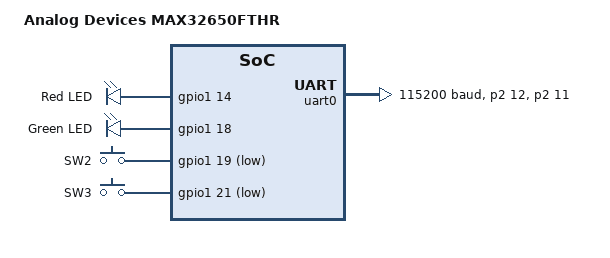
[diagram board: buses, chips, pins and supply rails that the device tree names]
/*
 * Copyright (c) 2025 Analog Devices, Inc.
 *
 * SPDX-License-Identifier: Apache-2.0
 */

/dts-v1/;

#include <adi/max32/max32650.dtsi>
#include <adi/max32/max32650-pinctrl.dtsi>
#include <zephyr/dt-bindings/gpio/adi-max32-gpio.h>
#include <zephyr/dt-bindings/input/input-event-codes.h>

/ {
	model = "Analog Devices MAX32650FTHR";
	compatible = "adi,max32650fthr";

	chosen {
		zephyr,console = &uart0;
		zephyr,shell-uart = &uart0;
		zephyr,sram = &sram0;
		zephyr,flash = &flash0;
	};

	leds {
		compatible = "gpio-leds";

		led1: led_1 {
			gpios = <&gpio1 14 GPIO_ACTIVE_HIGH>;
			label = "Red LED";
		};

		led2: led_2 {
			gpios = <&gpio1 18 GPIO_ACTIVE_HIGH>;
			label = "Green LED";
		};
	};

	buttons {
		compatible = "gpio-keys";

		pb1: pb1 {
			gpios = <&gpio1 19 (GPIO_PULL_UP | GPIO_ACTIVE_LOW)>;
			label = "SW2";
			zephyr,code = <INPUT_KEY_0>;
		};

		pb2: pb2 {
			gpios = <&gpio1 21 (GPIO_PULL_UP | GPIO_ACTIVE_LOW)>;
			label = "SW3";
			zephyr,code = <INPUT_KEY_1>;
		};
	};

	/* These aliases are provided for compatibility with samples */
	aliases {
		led0 = &led1;
		led1 = &led2;
	};
};

&uart0 {
	pinctrl-0 = <&uart0_tx_p2_12 &uart0_rx_p2_11>;
	pinctrl-names = "default";
	current-speed = <115200>;
	data-bits = <8>;
	parity = "none";
	status = "okay";
};

&clk_ipo {
	status = "okay";
};

&gpio0 {
	status = "okay";
};

&gpio1 {
	status = "okay";
};

&gpio2 {
	status = "okay";
};

&gpio3 {
	status = "okay";
};
